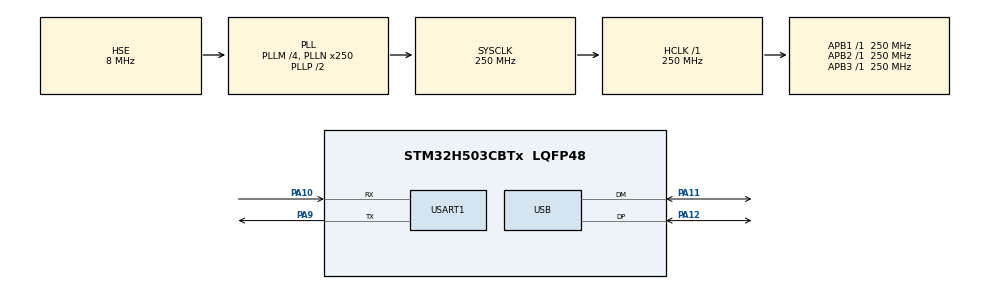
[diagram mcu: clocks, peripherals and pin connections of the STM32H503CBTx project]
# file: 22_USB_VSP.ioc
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GPDMA1.DIRECTION_GPDMACH0=DMA_MEMORY_TO_MEMORY
GPDMA1.IPHANDLE_GPDMACH0-SIMPLEREQUEST_GPDMACH0=__NULL
GPDMA1.REQUEST_GPDMACH0=GPDMA1_REQUEST_USART1_TX
GPDMA1.SRCINC_GPDMACH0=DMA_SINC_INCREMENTED
Mcu.Family=STM32H5
Mcu.Name=STM32H503CBTx
Mcu.Package=LQFP48
NVIC.GPDMA1_Channel0_IRQn=true\:0\:0\:false\:false\:true\:true\:false\:true\:true
NVIC.PriorityGroup=NVIC_PRIORITYGROUP_4
NVIC.TIM6_IRQn=true\:15\:0\:false\:false\:true\:false\:false\:true\:true
NVIC.TimeBase=TIM6_IRQn
NVIC.TimeBaseIP=TIM6
NVIC.USART1_IRQn=true\:6\:0\:true\:false\:true\:false\:true\:true\:true
NVIC.USB_DRD_FS_IRQn=true\:7\:0\:true\:false\:true\:false\:true\:true\:true
PA10.Mode=Asynchronous
PA10.Signal=USART1_RX
PA11.GPIO_PuPd=GPIO_PULLUP
PA11.GPIO_Speed=GPIO_SPEED_FREQ_VERY_HIGH
PA11.Mode=Device
PA11.Signal=USB_DM
PA12.GPIO_PuPd=GPIO_PULLUP
PA12.GPIO_Speed=GPIO_SPEED_FREQ_VERY_HIGH
PA12.Mode=Device
PA12.Signal=USB_DP
PA9.Mode=Asynchronous
PA9.Signal=USART1_TX
PC14-OSC32_IN(OSC32_IN).Mode=LSE-External-Oscillator
PC14-OSC32_IN(OSC32_IN).Signal=RCC_OSC32_IN
PC15-OSC32_OUT(OSC32_OUT).Mode=LSE-External-Oscillator
PC15-OSC32_OUT(OSC32_OUT).Signal=RCC_OSC32_OUT
PH0-OSC_IN(PH0).Mode=HSE-External-Oscillator
PH0-OSC_IN(PH0).Signal=RCC_OSC_IN
PH1-OSC_OUT(PH1).Mode=HSE-External-Oscillator
PH1-OSC_OUT(PH1).Signal=RCC_OSC_OUT
PWR.pwrPrivilege=PWR_PRIVILEGE_YES
ProjectManager.HeapSize=0x200
ProjectManager.StackSize=0x400
ProjectManager.TargetToolchain=STM32CubeIDE
RCC.ADCFreq_Value=250000000
RCC.AHBFreq_Value=250000000
RCC.APB1Freq_Value=250000000
RCC.APB1TimFreq_Value=250000000
RCC.APB2Freq_Value=250000000
RCC.APB2TimFreq_Value=250000000
RCC.APB3Freq_Value=250000000
RCC.CSI_VALUE=4000000
RCC.CortexFreq_Value=250000000
RCC.EPOD_VALUE=8000000
RCC.HCLKFreq_Value=250000000
RCC.HSE_VALUE=8000000
RCC.HSI48_VALUE=48000000
RCC.HSI_VALUE=64000000
RCC.LSIRC_VALUE=32000
RCC.PLLM=4
RCC.PLLN=250
RCC.PLLSourceVirtual=RCC_PLL1_SOURCE_HSE
RCC.SYSCLKFreq_VALUE=250000000
RCC.SYSCLKSource=RCC_SYSCLKSOURCE_PLLCLK
RCC.USBFreq_Value=48000000
RCC.VCOOutputFreq_Value=500000000
USART1.VirtualMode=VM_ASYNC
USB.VirtualMode=Device_Only
USBX.BSP.number=1
USBX.Core_System=1
USBX.REG_USBX_DEVICE_CON_CK=0
USBX.USBD_CDCACM_EPINCMD_ADDR=2
USBX.USBD_CDCACM_EPIN_ADDR=1
USBX.USBD_PID=22336
USBX.USBD_PRODUCT_STRING=STM32 Virtual ComPort
USBX.USBD_SERIAL_NUMBER=CDC_ACM001
USBX.USBX_DEVICE_SYS_SIZE=4*1024
USBX.UX_DEVICE_APP_MEM_POOL_SIZE=8192
USBX.UX_DEVICE_CDC_ACM=1
USBX.UX_DEVICE_CLASS_CDC_ACM_WRITE_AUTO_ZLP=1
USBX.UX_Device_Controller=1
USBX.UX_Device_CoreStack=1
USBX.UX_ENFORCE_SAFE_ALIGNMENT=0
USBX.UX_MAX_SLAVE_CLASS_DRIVER=1
USBX.UX_SLAVE_REQUEST_DATA_MAX_LENGTH=512
USBX0.BSP.STBoard=false
USBX0.BSP.api=Unknown
USBX0.BSP.instance=USB
USBX0.BSP.ip=USB
USBX0.BSP.mode=Device_Only
USBX0.BSP.name=USB_Device
USBX0.BSP.solution=USB
VP_GPDMA1_VS_GPDMACH0.Mode=SIMPLEREQUEST_GPDMACH0
VP_ICACHE_VS_ICACHE.Mode=DefaultMode
VP_PWR_VS_SECSignals.Mode=Security/Privilege
VP_RCC_USB.Mode=CRS SYNC Source USB
VP_SYS_VS_tim6.Mode=TIM6
VP_THREADX_VS_RTOSJjThreadXJjCoreJjDefault.Mode=Core_Default
VP_USBX_Core_System.Mode=Core_System
VP_USBX_UX\ Device\ CDC\ ACM\ Class_FS.Mode=UX_Device_class_CDC_ACM_FS
VP_USBX_UX\ Device\ Controller_FS.Mode=UX_Device_Controller_FS
VP_USBX_UX\ Device\ CoreStack_FS.Mode=UX_Device_CoreStack_FS
board=custom

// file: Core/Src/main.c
/**
 ****************************************************************************************************
 * @file        main.c
 * @author      ALIENTEK
 * @brief       USB_VSP code
 * @license     Copyright (C) 2012-2024, ALIENTEK
 ****************************************************************************************************
 * @attention
 *
 * platform     : ALIENTEK M48-STM32H503 board
 * website      : www.alientek.com
 * forum        : www.openedv.com/forum.php
 *
 * change logs  ：
 * version      data         notes
 * V1.0         20240309     the first version
 *
 ****************************************************************************************************
 */

/* USER CODE BEGIN Header */

/* USER CODE END Header */
#include "app_threadx.h"
#include "main.h"
#include "gpdma.h"
#include "icache.h"
#include "usart.h"
#include "usb.h"
#include "gpio.h"

/* USER CODE BEGIN PV */
extern UART_HandleTypeDef huart1;
/* USER CODE END PV */

void SystemClock_Config(void);

int main(void)
{

  /* MCU Configuration--------------------------------------------------------*/

  /* Reset of all peripherals, Initializes the Flash interface and the Systick. */
  HAL_Init();

  /* Configure the system clock */
  SystemClock_Config();

  /* Initialize all configured peripherals */
  MX_GPIO_Init();
  MX_GPDMA1_Init();
  MX_ICACHE_Init();
  MX_USART1_UART_Init();

  MX_ThreadX_Init();

  /* We should never get here as control is now taken by the scheduler */
  /* Infinite loop */
  while (1)
  {

  }
}

void SystemClock_Config(void)
{
  RCC_OscInitTypeDef RCC_OscInitStruct = {0};
  RCC_ClkInitTypeDef RCC_ClkInitStruct = {0};
  RCC_CRSInitTypeDef RCC_CRSInitStruct = {0};

  /** Configure the main internal regulator output voltage
  */
  __HAL_PWR_VOLTAGESCALING_CONFIG(PWR_REGULATOR_VOLTAGE_SCALE0);

  while(!__HAL_PWR_GET_FLAG(PWR_FLAG_VOSRDY)) {}

  /** Initializes the RCC Oscillators according to the specified parameters
  * in the RCC_OscInitTypeDef structure.
  */
  RCC_OscInitStruct.OscillatorType = RCC_OSCILLATORTYPE_HSI48|RCC_OSCILLATORTYPE_HSE;
  RCC_OscInitStruct.HSEState = RCC_HSE_ON;
  RCC_OscInitStruct.HSI48State = RCC_HSI48_ON;
  RCC_OscInitStruct.PLL.PLLState = RCC_PLL_ON;
  RCC_OscInitStruct.PLL.PLLSource = RCC_PLL1_SOURCE_HSE;
  RCC_OscInitStruct.PLL.PLLM = 4;
  RCC_OscInitStruct.PLL.PLLN = 250;
  RCC_OscInitStruct.PLL.PLLP = 2;
  RCC_OscInitStruct.PLL.PLLQ = 2;
  RCC_OscInitStruct.PLL.PLLR = 2;
  RCC_OscInitStruct.PLL.PLLRGE = RCC_PLL1_VCIRANGE_1;
  RCC_OscInitStruct.PLL.PLLVCOSEL = RCC_PLL1_VCORANGE_WIDE;
  RCC_OscInitStruct.PLL.PLLFRACN = 0;
  if (HAL_RCC_OscConfig(&RCC_OscInitStruct) != HAL_OK)
  {
    Error_Handler();
  }

  /** Initializes the CPU, AHB and APB buses clocks
  */
  RCC_ClkInitStruct.ClockType = RCC_CLOCKTYPE_HCLK|RCC_CLOCKTYPE_SYSCLK
                              |RCC_CLOCKTYPE_PCLK1|RCC_CLOCKTYPE_PCLK2
                              |RCC_CLOCKTYPE_PCLK3;
  RCC_ClkInitStruct.SYSCLKSource = RCC_SYSCLKSOURCE_PLLCLK;
  RCC_ClkInitStruct.AHBCLKDivider = RCC_SYSCLK_DIV1;
  RCC_ClkInitStruct.APB1CLKDivider = RCC_HCLK_DIV1;
  RCC_ClkInitStruct.APB2CLKDivider = RCC_HCLK_DIV1;
  RCC_ClkInitStruct.APB3CLKDivider = RCC_HCLK_DIV1;

  if (HAL_RCC_ClockConfig(&RCC_ClkInitStruct, FLASH_LATENCY_5) != HAL_OK)
  {
    Error_Handler();
  }

  /** Enable the CRS APB clock
  */
  __HAL_RCC_CRS_CLK_ENABLE();

  /** Configures CRS
  */
  RCC_CRSInitStruct.Prescaler = RCC_CRS_SYNC_DIV1;
  RCC_CRSInitStruct.Source = RCC_CRS_SYNC_SOURCE_USB;
  RCC_CRSInitStruct.Polarity = RCC_CRS_SYNC_POLARITY_RISING;
  RCC_CRSInitStruct.ReloadValue = __HAL_RCC_CRS_RELOADVALUE_CALCULATE(48000000,1000);
  RCC_CRSInitStruct.ErrorLimitValue = 34;
  RCC_CRSInitStruct.HSI48CalibrationValue = 32;

  HAL_RCCEx_CRSConfig(&RCC_CRSInitStruct);
}

void HAL_TIM_PeriodElapsedCallback(TIM_HandleTypeDef *htim)
{
  if (htim->Instance == TIM6) {
    HAL_IncTick();
  }
}

void Error_Handler(void)
{
  __disable_irq();
  while (1)
  {
  }
}
